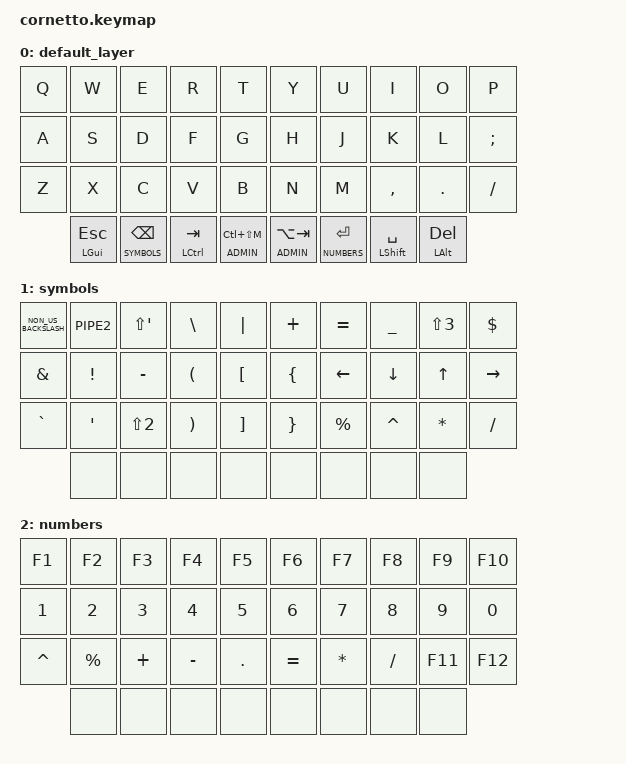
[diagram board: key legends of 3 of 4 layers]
#include <behaviors.dtsi>
#include <dt-bindings/zmk/keys.h>
#include <dt-bindings/zmk/bt.h>
#include <dt-bindings/zmk/mouse.h>

#define DEFAULT 0
#define SYMBOLS 1
#define NUMBERS 2
#define ADMIN   3

/ {
    
    behaviors {
        rot_mwh: behavior_sensor_rotate_kp {
            compatible = "zmk,behavior-sensor-rotate-var";
            label = "ENC_KP";
            #sensor-binding-cells = <2>;
            bindings = <&mwh>, <&mwh>;
        };
    };
    
    keymap {
        compatible = "zmk,keymap";

        default_layer {
            bindings = <
&kp Q    &kp W             &kp E                  &kp R                 &kp T                &kp Y              &kp U               &kp I                 &kp O                &kp P 
&kp A    &kp S             &kp D                  &kp F                 &kp G                &kp H              &kp J               &kp K                 &kp L                &kp SEMI
&kp Z    &kp X             &kp C                  &kp V                 &kp B                &kp N              &kp M               &kp COMMA             &kp DOT              &kp SLASH
         &mt LEFT_GUI ESC  &lt SYMBOLS BACKSPACE  &mt LEFT_CONTROL TAB  &lt ADMIN LC(LS(M))  &lt ADMIN LA(TAB)  &lt NUMBERS RETURN  &mt LEFT_SHIFT SPACE  &mt LEFT_ALT DELETE
            >;

            sensor-bindings = <&inc_dec_kp C_VOL_DN C_VOL_UP &rot_mwh SCROLL_UP SCROLL_DOWN>;
        };

        symbols {
            bindings = <
&kp NON_US_BACKSLASH  &kp PIPE2         &kp LS(SINGLE_QUOTE)  &kp BACKSLASH          &kp PIPE           &kp PLUS         &kp EQUAL       &kp UNDERSCORE  &kp LS(N3)    &kp DOLLAR
&kp AMPERSAND         &kp EXCLAMATION   &kp MINUS             &kp LEFT_PARENTHESIS   &kp LEFT_BRACKET   &kp LEFT_BRACE   &kp LEFT_ARROW  &kp DOWN        &kp UP_ARROW  &kp RIGHT_ARROW
&kp GRAVE             &kp SINGLE_QUOTE  &kp LS(N2)            &kp RIGHT_PARENTHESIS  &kp RIGHT_BRACKET  &kp RIGHT_BRACE  &kp PERCENT     &kp CARET       &kp ASTERISK  &kp SLASH
                      &none             &none                 &none                  &none              &none            &none           &none           &none
            >;
        };

        numbers {
            bindings = <
&kp F1     &kp F2       &kp F3    &kp F4     &kp F5   &kp F6     &kp F7        &kp F8     &kp F9   &kp F10
&kp N1     &kp N2       &kp N3    &kp N4     &kp N5   &kp N6     &kp N7        &kp N8     &kp N9   &kp N0
&kp CARET  &kp PERCENT  &kp PLUS  &kp MINUS  &kp DOT  &kp EQUAL  &kp ASTERISK  &kp SLASH  &kp F11  &kp F12
           &none        &none     &none      &none    &none      &none         &none      &none
            >;
        };
        
        admin {
            bindings = <
&bt BT_CLR  &none  &none       &none       &none  &none  &none  &none  &none  &none
&none       &none  &bt BT_PRV  &bt BT_NXT  &none  &none  &none  &none  &none  &none
&none       &none  &none       &none       &none  &none  &none  &none  &none  &none
            &none  &none       &none       &none  &none  &none  &none  &none  &none
            >;
            
            sensor-bindings = <&inc_dec_kp C_VOL_DN C_VOL_UP &rot_mwh SCROLL_RIGHT SCROLL_LEFT>;
        };
    };
};
